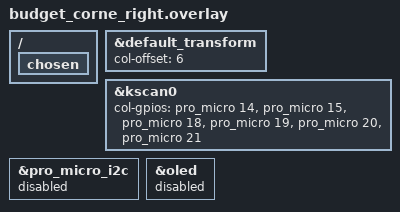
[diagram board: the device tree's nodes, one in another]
#include "budget_corne.dtsi"

&default_transform {
	col-offset = <6>;
};

/ {
	chosen {
		/delete-property/ zephyr,display;
	};
};

&kscan0 {
	col-gpios
		= <&pro_micro 14 GPIO_ACTIVE_HIGH>
		, <&pro_micro 15 GPIO_ACTIVE_HIGH>
		, <&pro_micro 18 GPIO_ACTIVE_HIGH>
		, <&pro_micro 19 GPIO_ACTIVE_HIGH>
		, <&pro_micro 20 GPIO_ACTIVE_HIGH>
		, <&pro_micro 21 GPIO_ACTIVE_HIGH>
		;
};

&pro_micro_i2c {
	status = "disabled";
};

&oled {
	status = "disabled";
};
